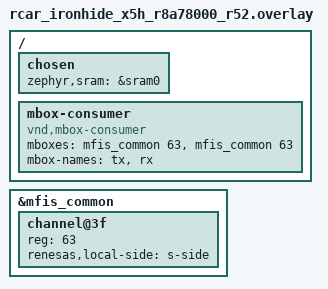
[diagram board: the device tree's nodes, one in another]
/*
 * Copyright (c) 2026 Renesas Electronics Corporation
 * SPDX-License-Identifier: Apache-2.0
 */

/ {
	chosen {
		zephyr,sram = &sram0;
	};

	mbox-consumer {
		compatible = "vnd,mbox-consumer";
		mboxes = <&mfis_common 63>, <&mfis_common 63>;
		mbox-names = "tx", "rx";
	};
};

&mfis_common {
	status = "okay";

	channel@3f {
		reg = <63>;
		renesas,local-side = "s-side";
	};
};
